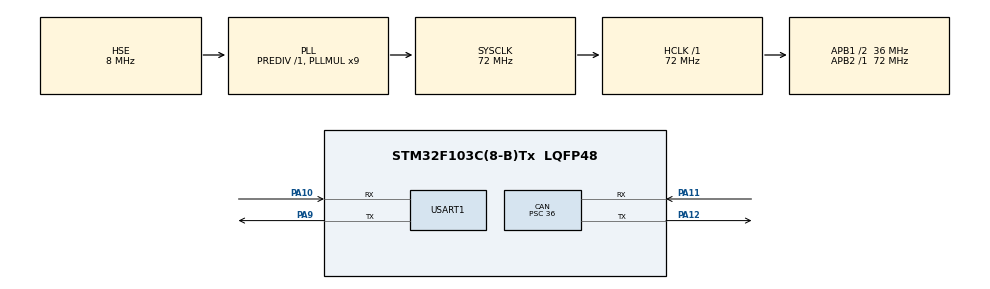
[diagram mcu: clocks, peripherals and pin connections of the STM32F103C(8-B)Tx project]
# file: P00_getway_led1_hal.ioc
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CAN.ABOM=ENABLE
CAN.AWUM=ENABLE
CAN.BS1=CAN_BS1_2TQ
CAN.BS2=CAN_BS2_2TQ
CAN.CalculateBaudRate=200000
CAN.CalculateTimeBit=5000
CAN.CalculateTimeQuantum=1000.0
CAN.Mode=CAN_MODE_NORMAL
CAN.Prescaler=36
Dma.Request0=USART1_RX
Dma.USART1_RX.0.Direction=DMA_PERIPH_TO_MEMORY
Dma.USART1_RX.0.Instance=DMA1_Channel5
Dma.USART1_RX.0.MemDataAlignment=DMA_MDATAALIGN_BYTE
Dma.USART1_RX.0.MemInc=DMA_MINC_ENABLE
Dma.USART1_RX.0.Mode=DMA_CIRCULAR
Dma.USART1_RX.0.PeriphDataAlignment=DMA_PDATAALIGN_BYTE
Dma.USART1_RX.0.PeriphInc=DMA_PINC_DISABLE
Dma.USART1_RX.0.Priority=DMA_PRIORITY_HIGH
Mcu.Family=STM32F1
Mcu.Name=STM32F103C(8-B)Tx
Mcu.Package=LQFP48
NVIC.DMA1_Channel5_IRQn=true\:0\:0\:false\:false\:true\:false\:true\:true
NVIC.PriorityGroup=NVIC_PRIORITYGROUP_4
NVIC.USART1_IRQn=true\:5\:0\:true\:false\:true\:true\:true\:true
PA10.Mode=Asynchronous
PA10.Signal=USART1_RX
PA11.Mode=CAN_Activate
PA11.Signal=CAN_RX
PA12.Mode=CAN_Activate
PA12.Signal=CAN_TX
PA13.Mode=Serial_Wire
PA13.Signal=SYS_JTMS-SWDIO
PA14.Mode=Serial_Wire
PA14.Signal=SYS_JTCK-SWCLK
PA9.Mode=Asynchronous
PA9.Signal=USART1_TX
PC14-OSC32_IN.Mode=LSE-External-Oscillator
PC14-OSC32_IN.Signal=RCC_OSC32_IN
PC15-OSC32_OUT.Mode=LSE-External-Oscillator
PC15-OSC32_OUT.Signal=RCC_OSC32_OUT
PD0-OSC_IN.Mode=HSE-External-Oscillator
PD0-OSC_IN.Signal=RCC_OSC_IN
PD1-OSC_OUT.Mode=HSE-External-Oscillator
PD1-OSC_OUT.Signal=RCC_OSC_OUT
ProjectManager.HeapSize=0x200
ProjectManager.StackSize=0x400
ProjectManager.TargetToolchain=MDK-ARM V5.32
RCC.AHBFreq_Value=72000000
RCC.APB1CLKDivider=RCC_HCLK_DIV2
RCC.APB1Freq_Value=36000000
RCC.APB1TimFreq_Value=72000000
RCC.APB2Freq_Value=72000000
RCC.APB2TimFreq_Value=72000000
RCC.HCLKFreq_Value=72000000
RCC.PLLMUL=RCC_PLL_MUL9
RCC.PLLSourceVirtual=RCC_PLLSOURCE_HSE
RCC.SYSCLKFreq_VALUE=72000000
RCC.SYSCLKSource=RCC_SYSCLKSOURCE_PLLCLK
RCC.USBFreq_Value=72000000
USART1.VirtualMode=VM_ASYNC
VP_CRC_VS_CRC.Mode=CRC_Activate
board=custom

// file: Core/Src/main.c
/* USER CODE BEGIN Header */
/**
  ******************************************************************************
  * @file           : main.c
  * @brief          : Main program body
  ******************************************************************************
  * @attention
  *
  * Copyright (c) 2026 STMicroelectronics.
  * All rights reserved.
  *
  * This software is licensed under terms that can be found in the LICENSE file
  * in the root directory of this software component.
  * If no LICENSE file comes with this software, it is provided AS-IS.
  *
  ******************************************************************************
  */
/* USER CODE END Header */
#include "main.h"
#include "can.h"
#include "crc.h"
#include "dma.h"
#include "usart.h"
#include "gpio.h"

/* USER CODE BEGIN Includes */
#include "can_buf.h"
#include "app_update.h"
#include "app_bootloader.h"
#include "uart_buf.h"
#include "fw_cache_conf.h"
#include <stdio.h>
/* USER CODE END Includes */

/* USER CODE BEGIN PV */
static CAN_Buf_t can_ctx;
static AppUpdate_t update_ctx;
// static AppBootloader_t bl_ctx;
/* USER CODE END PV */

void SystemClock_Config(void);

int main(void)
{

  /* MCU Configuration--------------------------------------------------------*/

  /* Reset of all peripherals, Initializes the Flash interface and the Systick. */
  HAL_Init();

  /* Configure the system clock */
  SystemClock_Config();

  /* Initialize all configured peripherals */
  MX_GPIO_Init();
  MX_DMA_Init();
  MX_CAN_Init();
  MX_USART1_UART_Init();
  MX_CRC_Init();
  /* USER CODE BEGIN 2 */
  CAN_Buf_Init(&can_ctx, &hcan);

  /* 串口下载状态机 — 已通过串口下载固件到 Flash，注释掉防止上电重新请求 */
  /* AppBootloader_Init(&bl_ctx); */

  /* CAN 更新状态机：固件数据指向 Flash 缓存区，大小 = 已下载的 1344 字节 */
  AppUpdate_Init(&update_ctx, &can_ctx,
                 (const uint8_t *)FW_CACHE_ADDR, 1344);

  UART_DMA_Rx_Init();            /* 启动 USART1 DMA + IDLE 接收 */
  /* USER CODE END 2 */

  /* Infinite loop */
  while (1)
  {

    /* USER CODE BEGIN 3 */
    /* 串口下载状态机已注释 — 固件已存在于 Flash (0x08004000) */
    /* AppBootloader_Process(&bl_ctx); */

    /* CAN 更新状态机：直接使用 Flash 中已存储的固件 */
    AppUpdate_Poll(&update_ctx);
  }
  /* USER CODE END 3 */
}

void SystemClock_Config(void)
{
  RCC_OscInitTypeDef RCC_OscInitStruct = {0};
  RCC_ClkInitTypeDef RCC_ClkInitStruct = {0};

  /** Initializes the RCC Oscillators according to the specified parameters
  * in the RCC_OscInitTypeDef structure.
  */
  RCC_OscInitStruct.OscillatorType = RCC_OSCILLATORTYPE_HSE;
  RCC_OscInitStruct.HSEState = RCC_HSE_ON;
  RCC_OscInitStruct.HSEPredivValue = RCC_HSE_PREDIV_DIV1;
  RCC_OscInitStruct.HSIState = RCC_HSI_ON;
  RCC_OscInitStruct.PLL.PLLState = RCC_PLL_ON;
  RCC_OscInitStruct.PLL.PLLSource = RCC_PLLSOURCE_HSE;
  RCC_OscInitStruct.PLL.PLLMUL = RCC_PLL_MUL9;
  if (HAL_RCC_OscConfig(&RCC_OscInitStruct) != HAL_OK)
  {
    Error_Handler();
  }

  /** Initializes the CPU, AHB and APB buses clocks
  */
  RCC_ClkInitStruct.ClockType = RCC_CLOCKTYPE_HCLK|RCC_CLOCKTYPE_SYSCLK
                              |RCC_CLOCKTYPE_PCLK1|RCC_CLOCKTYPE_PCLK2;
  RCC_ClkInitStruct.SYSCLKSource = RCC_SYSCLKSOURCE_PLLCLK;
  RCC_ClkInitStruct.AHBCLKDivider = RCC_SYSCLK_DIV1;
  RCC_ClkInitStruct.APB1CLKDivider = RCC_HCLK_DIV2;
  RCC_ClkInitStruct.APB2CLKDivider = RCC_HCLK_DIV1;

  if (HAL_RCC_ClockConfig(&RCC_ClkInitStruct, FLASH_LATENCY_2) != HAL_OK)
  {
    Error_Handler();
  }
}

void Error_Handler(void)
{
  __disable_irq();
  while (1)
  {
  }
}
